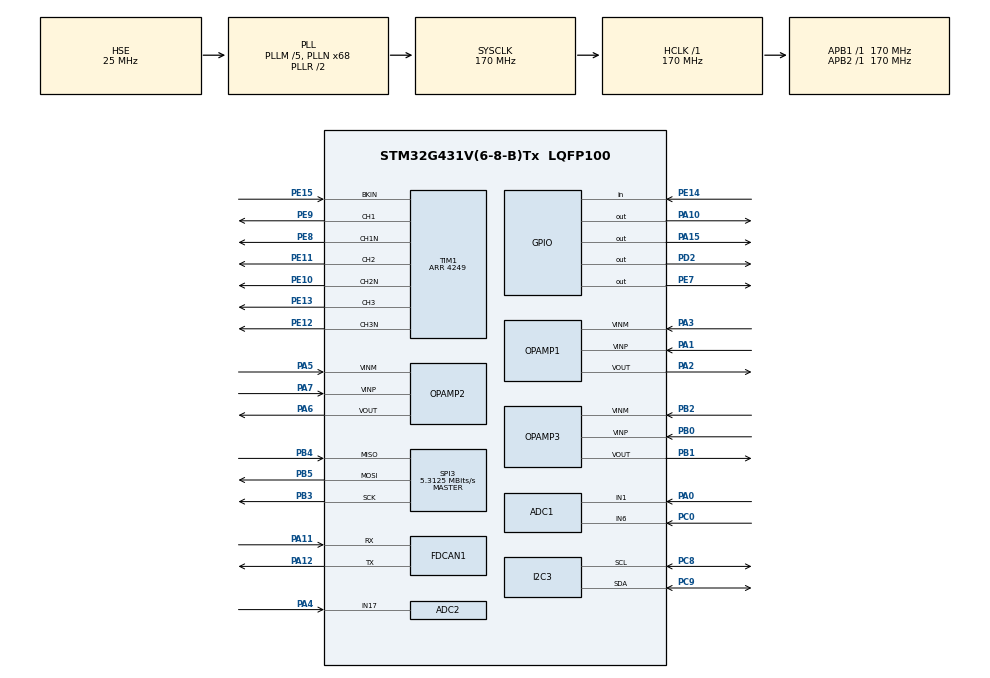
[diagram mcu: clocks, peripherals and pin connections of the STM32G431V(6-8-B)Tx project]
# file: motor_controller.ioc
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ADC1.Channel-0\#ChannelRegularConversion=ADC_CHANNEL_6
ADC1.Channel-1\#ChannelRegularConversion=ADC_CHANNEL_1
ADC1.ClockPrescaler=ADC_CLOCK_SYNC_PCLK_DIV4
ADC1.EOCSelection=ADC_EOC_SEQ_CONV
ADC1.NbrOfConversion=2
ADC1.NbrOfConversionFlag=1
ADC1.OffsetNumber-0\#ChannelRegularConversion=ADC_OFFSET_NONE
ADC1.OffsetNumber-1\#ChannelRegularConversion=ADC_OFFSET_NONE
ADC1.Overrun=ADC_OVR_DATA_OVERWRITTEN
ADC1.Rank-0\#ChannelRegularConversion=1
ADC1.Rank-1\#ChannelRegularConversion=2
ADC1.SamplingTime-0\#ChannelRegularConversion=ADC_SAMPLETIME_247CYCLES_5
ADC1.SamplingTime-1\#ChannelRegularConversion=ADC_SAMPLETIME_247CYCLES_5
ADC1.master=1
ADC2.Channel-0\#ChannelRegularConversion=ADC_CHANNEL_17
ADC2.ClockPrescaler=ADC_CLOCK_SYNC_PCLK_DIV4
ADC2.EnableAnalogWatchDog2=false
ADC2.NbrOfConversionFlag=1
ADC2.OffsetNumber-0\#ChannelRegularConversion=ADC_OFFSET_NONE
ADC2.Rank-0\#ChannelRegularConversion=1
ADC2.SamplingTime-0\#ChannelRegularConversion=ADC_SAMPLETIME_247CYCLES_5
FDCAN1.CalculateBaudRateNominal=3541666
FDCAN1.CalculateTimeBitNominal=282
FDCAN1.CalculateTimeQuantumNominal=94.11764705882354
I2C3.Timing=0x40B285C2
Mcu.Family=STM32G4
Mcu.Name=STM32G431V(6-8-B)Tx
Mcu.Package=LQFP100
NVIC.PriorityGroup=NVIC_PRIORITYGROUP_4
OPAMP1.PowerMode=OPAMP_POWERMODE_HIGHSPEED
OPAMP2.PowerMode=OPAMP_POWERMODE_HIGHSPEED
OPAMP3.PowerMode=OPAMP_POWERMODE_HIGHSPEED
PA0.Mode=IN1-Single-Ended
PA0.Signal=ADC1_IN1
PA1.Mode=Standalone
PA1.Signal=OPAMP1_VINP
PA10.GPIO_PuPd=GPIO_PULLDOWN
PA10.Signal=GPIO_Output
PA11.Mode=FDCAN_Activate
PA11.Signal=FDCAN1_RX
PA12.Mode=FDCAN_Activate
PA12.Signal=FDCAN1_TX
PA13.Mode=Serial_Wire
PA13.Signal=SYS_JTMS-SWDIO
PA14.Mode=Serial_Wire
PA14.Signal=SYS_JTCK-SWCLK
PA15.GPIO_PuPd=GPIO_PULLUP
PA15.PinState=GPIO_PIN_SET
PA15.Signal=GPIO_Output
PA2.Mode=Standalone
PA2.Signal=OPAMP1_VOUT
PA3.Mode=Standalone
PA3.Signal=OPAMP1_VINM
PA4.Mode=IN17-Single-Ended
PA4.Signal=ADC2_IN17
PA5.Mode=Standalone
PA5.Signal=OPAMP2_VINM
PA6.Mode=Standalone
PA6.Signal=OPAMP2_VOUT
PA7.Mode=Standalone
PA7.Signal=OPAMP2_VINP
PB0.Mode=Standalone
PB0.Signal=OPAMP3_VINP
PB1.Mode=Standalone
PB1.Signal=OPAMP3_VOUT
PB2.Mode=Standalone
PB2.Signal=OPAMP3_VINM
PB3.Mode=Full_Duplex_Master
PB3.Signal=SPI3_SCK
PB4.Mode=Full_Duplex_Master
PB4.Signal=SPI3_MISO
PB5.Mode=Full_Duplex_Master
PB5.Signal=SPI3_MOSI
PC0.Mode=IN6-Single-Ended
PC0.Signal=ADC1_IN6
PC8.Mode=I2C
PC8.Signal=I2C3_SCL
PC9.Mode=I2C
PC9.Signal=I2C3_SDA
PD2.Signal=GPIO_Output
PE10.Mode=PWM Generation2 CH2 CH2N
PE10.Signal=TIM1_CH2N
PE11.Signal=S_TIM1_CH2
PE12.Mode=PWM Generation3 CH3 CH3N
PE12.Signal=TIM1_CH3N
PE13.Signal=S_TIM1_CH3
PE14.Signal=GPIO_Input
PE15.GPIO_PuPd=GPIO_PULLUP
PE15.Mode=Activate-Break-Input
PE15.Signal=TIM1_BKIN
PE7.GPIO_PuPd=GPIO_PULLDOWN
PE7.Signal=GPIO_Output
PE8.Mode=PWM Generation1 CH1 CH1N
PE8.Signal=TIM1_CH1N
PE9.Signal=S_TIM1_CH1
PF0-OSC_IN.Mode=HSE-External-Oscillator
PF0-OSC_IN.Signal=RCC_OSC_IN
PF1-OSC_OUT.Mode=HSE-External-Oscillator
PF1-OSC_OUT.Signal=RCC_OSC_OUT
ProjectManager.HeapSize=0x200
ProjectManager.StackSize=0x400
ProjectManager.TargetToolchain=CMake
RCC.ADC12Freq_Value=170000000
RCC.AHBFreq_Value=170000000
RCC.APB1Freq_Value=170000000
RCC.APB1TimFreq_Value=170000000
RCC.APB2Freq_Value=170000000
RCC.APB2TimFreq_Value=170000000
RCC.CortexFreq_Value=170000000
RCC.EXTERNAL_CLOCK_VALUE=12288000
RCC.HCLKFreq_Value=170000000
RCC.HSE_VALUE=25000000
RCC.HSI48_VALUE=48000000
RCC.HSI_VALUE=16000000
RCC.LSE_VALUE=32768
RCC.PLLM=RCC_PLLM_DIV5
RCC.PLLN=68
RCC.PLLSourceVirtual=RCC_PLLSOURCE_HSE
RCC.SYSCLKFreq_VALUE=170000000
RCC.SYSCLKSource=RCC_SYSCLKSOURCE_PLLCLK
RCC.USBFreq_Value=170000000
RCC.VCOOutputFreq_Value=340000000
SH.S_TIM1_CH1.0=TIM1_CH1,PWM Generation1 CH1 CH1N
SH.S_TIM1_CH2.0=TIM1_CH2,PWM Generation2 CH2 CH2N
SH.S_TIM1_CH3.0=TIM1_CH3,PWM Generation3 CH3 CH3N
SPI3.BaudRatePrescaler=SPI_BAUDRATEPRESCALER_32
SPI3.CLKPhase=SPI_PHASE_2EDGE
SPI3.CRCCalculation=SPI_CRCCALCULATION_DISABLE
SPI3.CalculateBaudRate=5.3125 MBits/s
SPI3.DataSize=SPI_DATASIZE_16BIT
SPI3.Direction=SPI_DIRECTION_2LINES
SPI3.Mode=SPI_MODE_MASTER
SPI3.VirtualType=VM_MASTER
TIM1.BreakPolarity=TIM_BREAKPOLARITY_LOW
TIM1.Channel-PWM\ Generation1\ CH1\ CH1N=TIM_CHANNEL_1
TIM1.Channel-PWM\ Generation2\ CH2\ CH2N=TIM_CHANNEL_2
TIM1.Channel-PWM\ Generation3\ CH3\ CH3N=TIM_CHANNEL_3
TIM1.Channel-PWM\ Generation4\ No\ Output=TIM_CHANNEL_4
TIM1.CounterMode=TIM_COUNTERMODE_CENTERALIGNED1
TIM1.DeadTime=34
TIM1.PeriodNoDither=4249
TIM1.TIM_MasterOutputTrigger2=TIM_TRGO2_OC4REF_RISINGFALLING
VP_SYS_VS_DBSignals.Mode=DisableDeadBatterySignals
VP_TIM1_VS_ClockSourceINT.Mode=Internal
VP_TIM1_VS_no_output4.Mode=PWM Generation4 No Output
board=custom

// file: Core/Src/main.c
/* USER CODE BEGIN Header */
/**
  ******************************************************************************
  * @file           : main.c
  * @brief          : Main program body
  ******************************************************************************
  * @attention
  *
  * Copyright (c) 2026 STMicroelectronics.
  * All rights reserved.
  *
  * This software is licensed under terms that can be found in the LICENSE file
  * in the root directory of this software component.
  * If no LICENSE file comes with this software, it is provided AS-IS.
  *
  ******************************************************************************
  */
/* USER CODE END Header */
#include "main.h"
#include "adc.h"
#include "fdcan.h"
#include "i2c.h"
#include "opamp.h"
#include "spi.h"
#include "tim.h"
#include "gpio.h"

/* USER CODE BEGIN Includes */
#include "app/app.h"

/* USER CODE END Includes */

void SystemClock_Config(void);

int main(void)
{

  /* MCU Configuration--------------------------------------------------------*/

  /* Reset of all peripherals, Initializes the Flash interface and the Systick. */
  HAL_Init();

  /* Configure the system clock */
  SystemClock_Config();

  /* Initialize all configured peripherals */
  MX_GPIO_Init();
  MX_ADC1_Init();
  MX_ADC2_Init();
  MX_FDCAN1_Init();
  MX_I2C3_Init();
  MX_OPAMP1_Init();
  MX_OPAMP2_Init();
  MX_OPAMP3_Init();
  MX_SPI3_Init();
  MX_TIM1_Init();
  /* USER CODE BEGIN 2 */
  app_init();

  /* USER CODE END 2 */

  /* Infinite loop */
  while (1)
  {

    /* USER CODE BEGIN 3 */
    app_loop();
  }
  /* USER CODE END 3 */
}

void SystemClock_Config(void)
{
  RCC_OscInitTypeDef RCC_OscInitStruct = {0};
  RCC_ClkInitTypeDef RCC_ClkInitStruct = {0};

  /** Configure the main internal regulator output voltage
  */
  HAL_PWREx_ControlVoltageScaling(PWR_REGULATOR_VOLTAGE_SCALE1_BOOST);

  /** Initializes the RCC Oscillators according to the specified parameters
  * in the RCC_OscInitTypeDef structure.
  */
  RCC_OscInitStruct.OscillatorType = RCC_OSCILLATORTYPE_HSE;
  RCC_OscInitStruct.HSEState = RCC_HSE_ON;
  RCC_OscInitStruct.PLL.PLLState = RCC_PLL_ON;
  RCC_OscInitStruct.PLL.PLLSource = RCC_PLLSOURCE_HSE;
  RCC_OscInitStruct.PLL.PLLM = RCC_PLLM_DIV5;
  RCC_OscInitStruct.PLL.PLLN = 68;
  RCC_OscInitStruct.PLL.PLLP = RCC_PLLP_DIV2;
  RCC_OscInitStruct.PLL.PLLQ = RCC_PLLQ_DIV2;
  RCC_OscInitStruct.PLL.PLLR = RCC_PLLR_DIV2;
  if (HAL_RCC_OscConfig(&RCC_OscInitStruct) != HAL_OK)
  {
    Error_Handler();
  }

  /** Initializes the CPU, AHB and APB buses clocks
  */
  RCC_ClkInitStruct.ClockType = RCC_CLOCKTYPE_HCLK|RCC_CLOCKTYPE_SYSCLK
                              |RCC_CLOCKTYPE_PCLK1|RCC_CLOCKTYPE_PCLK2;
  RCC_ClkInitStruct.SYSCLKSource = RCC_SYSCLKSOURCE_PLLCLK;
  RCC_ClkInitStruct.AHBCLKDivider = RCC_SYSCLK_DIV1;
  RCC_ClkInitStruct.APB1CLKDivider = RCC_HCLK_DIV1;
  RCC_ClkInitStruct.APB2CLKDivider = RCC_HCLK_DIV1;

  if (HAL_RCC_ClockConfig(&RCC_ClkInitStruct, FLASH_LATENCY_4) != HAL_OK)
  {
    Error_Handler();
  }
}

void Error_Handler(void)
{
  __disable_irq();
  while (1)
  {
  }
}
